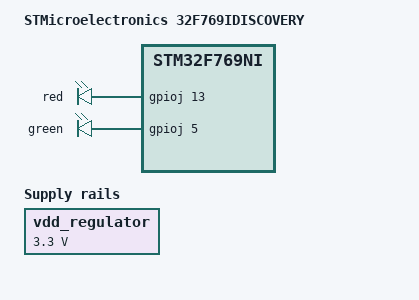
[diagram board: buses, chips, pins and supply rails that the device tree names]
/**
 * \file
 * \brief Devicetree for 32F769IDISCOVERY
 *
 * \author Copyright (C) 2017 elbe informatik GmbH
 * \author Copyright (C) 2017 Kamil Szczygiel http://www.distortec.com http://www.freddiechopin.info
 *
 * \par License
 * This Source Code Form is subject to the terms of the Mozilla Public License, v. 2.0. If a copy of the MPL was not
 * distributed with this file, You can obtain one at http://mozilla.org/MPL/2.0/.
 */

/dts-v1/;

#include "STM32F769NI.dtsi"

/ {
	compatible = "ST,32F769IDISCOVERY", "ST,STM32F769NI";
	model = "STMicroelectronics 32F769IDISCOVERY";

	leds {
		compatible = "gpio-leds";
		status = "okay";

		ld1 {
			gpios = <&gpioj 13 0>;
			label = "red";
			status = "okay";
		};

		ld2 {
			gpios = <&gpioj 5 0>;
			label = "green";
			status = "okay";
		};
	};

	regulators {
		#address-cells = <1>;
		#size-cells = <0>;

		vdd_regulator: regulator@0 {
			compatible = "regulator-fixed";
			reg = <0>;
			regulator-name = "VDD";
			regulator-min-microvolt = <3300000>;
			regulator-max-microvolt = <3300000>;
			regulator-always-on;
		};
	};
};

&clock_hse {
	ST,STM32-HSE-bypass;
	clock-frequency = <25000000>;
};

&gpioa {
	status = "okay";
};
&gpioj {
	status = "okay";
};
